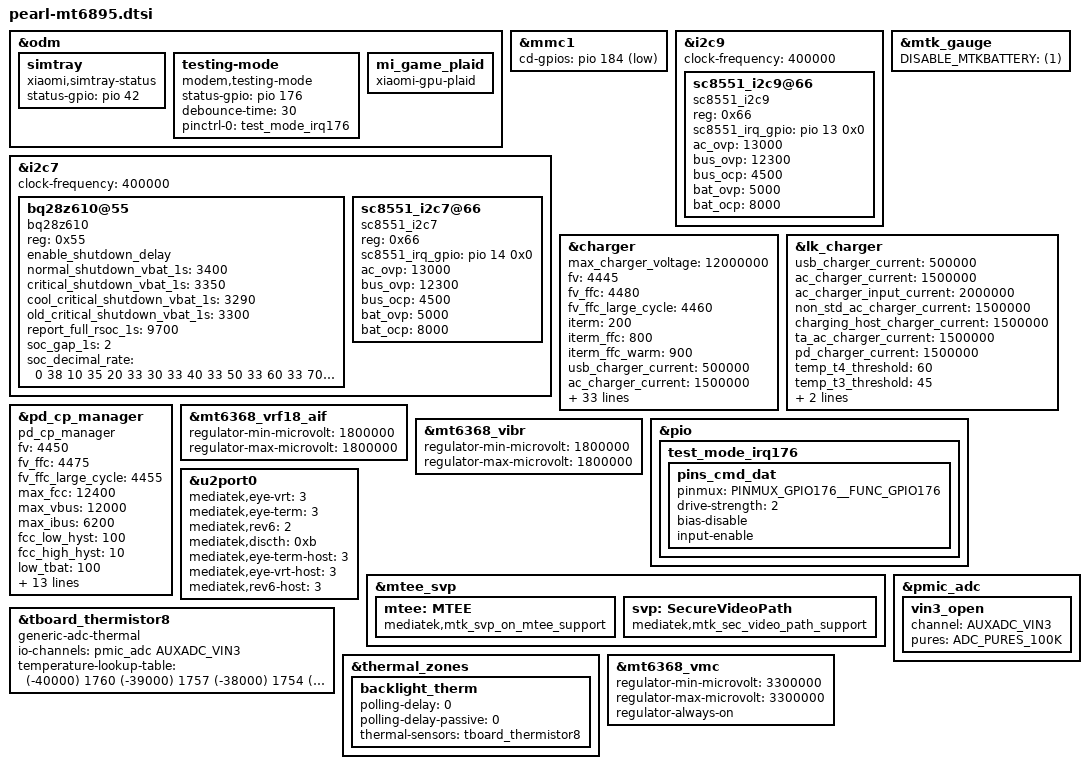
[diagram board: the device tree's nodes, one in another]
/*
this file is only for attribution of pearl
*/
#include "mediatek/xiaomi-mt6895-common.dtsi"
#include "mediatek/pearl_mt6895_camera_v4l2.dtsi"
#include "mediatek/xiaomi-pearl-mt6895-fingerprint.dtsi"
#include <dt-bindings/iio/mt635x-auxadc.h>
#include <dt-bindings/thermal/thermal.h>

&odm {
	simtray {
		compatible = "xiaomi,simtray-status";
		status-gpio =	<&pio 42 0>;
	};
};

&mmc1 {
	cd-gpios = <&pio 184 0x1>;
};

&i2c9 {
	clock-frequency = <400000>;
	status = "okay";

	sc8551_i2c9@66 {
		compatible = "sc8551_i2c9";
		reg = <0x66>;
		sc8551_irq_gpio = <&pio 13 0x0>;
		ac_ovp = <13000>;
		bus_ovp = <12300>;
		bus_ocp = <4500>;
		bat_ovp = <5000>;
		bat_ocp = <8000>;
	};
};

&i2c7 {
	clock-frequency = <400000>;
	status = "okay";
	bq28z610@55 {
		compatible = "bq28z610";
		reg = <0x55>;
		enable_shutdown_delay;
		normal_shutdown_vbat_1s = <3400>;
		critical_shutdown_vbat_1s = <3350>;
		cool_critical_shutdown_vbat_1s = <3290>;
		old_critical_shutdown_vbat_1s = <3300>;
		report_full_rsoc_1s = <9700>;
		soc_gap_1s = <2>;
		soc_decimal_rate = <
			0  38
			10 35
			20 33
			30 33
			40 33
			50 33
			60 33
			70 30
			80 25
			90 20
			95 10 >;
	};

	sc8551_i2c7@66 {
		compatible = "sc8551_i2c7";
		reg = <0x66>;
		sc8551_irq_gpio = <&pio 14 0x0>;
		ac_ovp = <13000>;
		bus_ovp = <12300>;
		bus_ocp = <4500>;
		bat_ovp = <5000>;
		bat_ocp = <8000>;
	};
};

&charger {
		max_charger_voltage = <12000000>;
		fv = <4445>;
		fv_ffc = <4480>;
		fv_ffc_large_cycle = <4460>;
		iterm = <200>;
		iterm_ffc = <800>;
		iterm_ffc_warm = <900>;
		usb_charger_current = <500000>;
		ac_charger_current = <1500000>;
		ac_charger_input_current = <1500000>;
		charging_host_charger_current = <1500000>;
		pd2_input_current = <1700000>;
		ffc_low_tbat = <150>;
		ffc_high_tbat = <480>;
		ffc_medium_tbat = <350>;
		ffc_high_soc = <95>;
		step_fallback_hyst = <25>;
		step_forward_hyst = <5>;
		jeita_fallback_hyst = <15>;
		jeita_forward_hyst = <6>;
		pearl_product;
		mt6368_moscon1_control;
		jeita_fcc_cfg = <(-100)	0	4200	1000	747
				1	50	4200	2390	2390
				51	100	4200	3386	3386
				101	150	4200	5826	5826
				151	474	4200    12400   12400
				475	600	4200	2490	2490>;
		jeita_fv_cfg = <(-100)	0	4440
				1	50	4450
				51	100	4450
				101	150	4450
				151	474	4480
				475	600	4100>;
		step_chg_cfg_low_cycle = <3000	3595	12310
					3596	4090	12310
					4091	4190	12310
					4191	4290	8875
					4291	4390	7380
					4391	4480	5786>;
		step_chg_cfg_high_cycle = <3000	3595	12310
					3596	3850	12310
					3851	4180	12310
					4181	4280	8575
					4281	4380	7180
					4381	4480	5486>;
		thermal_limit_dcp = <1800 1800 1800 1800 1800 1800 1800 1800 1800 1800 1800 1800 1700 1600 1400 1200>;
		thermal_limit_qc2 = <2500 2500 2500 2500 2500 2500 2500 2500 2500 2500 2500 2000 1500 1500 1000 500>;
		thermal_limit_qc3_18w = <2500 2500 2500 2500 2500 2500 2400 2300 2200 2100 1500 1000 800 700 600 500>;
		thermal_limit_qc3_27w = <2500 2500 2500 2500 2500 2500 2400 2300 2200 2100 1500 1000 800 700 600 500>;
		thermal_limit_qc35 = <2500 2500 2500 2500 2500 2500 2400 2300 2200 2100 1500 1000 800 700 600 500>;
		thermal_limit_pd = <12400 10000 9000 8000 7400 6100 5600 5000 4400 3500 3000 2400 2000 1500 1000 500>;
};

&mtk_gauge {
        DISABLE_MTKBATTERY = <(1)>;
};

&lk_charger {
		/* charging current */
		usb_charger_current = <500000>;
		ac_charger_current = <1500000>;
		ac_charger_input_current = <2000000>;
		non_std_ac_charger_current = <1500000>;
		charging_host_charger_current = <1500000>;
		ta_ac_charger_current = <1500000>;
		pd_charger_current = <1500000>;

		/* battery temperature protection */
		temp_t4_threshold = <60>;
		temp_t3_threshold = <45>;
		pre_charger_current = <250000>;
		fast_charge_voltage = <3100>;
};

&pd_cp_manager {
		compatible = "pd_cp_manager";
		fv = <4450>;
		fv_ffc = <4475>;
		fv_ffc_large_cycle = <4455>;
		max_fcc = <12400>;
		max_vbus = <12000>;
		max_ibus = <6200>;
		fcc_low_hyst = <100>;
		fcc_high_hyst = <10>;
		low_tbat = <100>;
		high_tbat = <480>;
		high_vbat = <4400>;
		high_soc = <95>;
		low_fcc = <2000>;
		cv_vbat = <4440>;
		cv_vbat_ffc = <4470>;
		cv_vbat_ffc_large_cycle = <4450>;
		cv_ibat = <2000>;
		cv_ibat_bypass = <1300>;
		vbus_low_gap_div = <400>;
		vbus_high_gap_div = <600>;
		min_pdo_vbus = <8000>;
		max_pdo_vbus = <11000>;

};

&mt6368_vrf18_aif {
	regulator-min-microvolt = <1800000>;
	regulator-max-microvolt = <1800000>;
};

&mt6368_vibr {
	regulator-min-microvolt = <1800000>;
	regulator-max-microvolt = <1800000>;
};

&pio {
	test_mode_irq176: test_mode_irq176 {
                pins_cmd_dat {
			pinmux = <PINMUX_GPIO176__FUNC_GPIO176>;
			drive-strength = <2>;
			bias-disable;
			input-enable;
		};
	};
};

&odm {
	testing-mode {
		compatible = "modem,testing-mode";
		status-gpio = <&pio 176 0>;
		debounce-time = <30>;
		pinctrl-names = "default";
		pinctrl-0 = <&test_mode_irq176 >;
	};
};

&odm {
	mi_game_plaid {
		compatible = "xiaomi-gpu-plaid";
	};
};

&u2port0{
		mediatek,eye-vrt = <3>;
		mediatek,eye-term = <3>;
		mediatek,rev6 = <2>;
		mediatek,discth = <0xb>;
		mediatek,eye-term-host = <3>;
		mediatek,eye-vrt-host = <3>;
		mediatek,rev6-host = <3>;
};

&mtee_svp {
	mtee: MTEE {
                   compatible = "mediatek,mtk_svp_on_mtee_support";
	};

	svp: SecureVideoPath {
                   compatible = "mediatek,mtk_sec_video_path_support";
	};
};

&pmic_adc {
	vin3_open {
		channel = <AUXADC_VIN3>;
		pures = <ADC_PURES_100K>;
	};
};

&tboard_thermistor8 {
		compatible = "generic-adc-thermal";
		#thermal-sensor-cells = <0>;
		io-channels = <&pmic_adc AUXADC_VIN3>;
		io-channel-names = "sensor-channel";
		temperature-lookup-table = <
			(-40000) 1760
			(-39000) 1757
			(-38000) 1754
			(-37000) 1751
			(-36000) 1747
			(-35000) 1744
			(-34000) 1740
			(-33000) 1736
			(-32000) 1731
			(-31000) 1727
			(-30000) 1722
			(-29000) 1716
			(-28000) 1711
			(-27000) 1705
			(-26000) 1699
			(-25000) 1693
			(-24000) 1686
			(-23000) 1679
			(-22000) 1672
			(-21000) 1664
			(-20000) 1656
			(-19000) 1648
			(-18000) 1639
			(-17000) 1630
			(-16000) 1620
			(-15000) 1610
			(-14000) 1599
			(-13000) 1588
			(-12000) 1577
			(-11000) 1565
			(-10000) 1553
			(-9000) 1540
			(-8000) 1527
			(-7000) 1514
			(-6000) 1500
			(-5000) 1485
			(-4000) 1470
			(-3000) 1455
			(-2000) 1439
			(-1000) 1423
			0 1406
			1000 1389
			2000 1372
			3000 1354
			4000 1335
			5000 1317
			6000 1298
			7000 1279
			8000 1259
			9000 1239
			10000 1219
			11000 1198
			12000 1178
			13000 1157
			14000 1136
			15000 1115
			16000 1093
			17000 1072
			18000 1050
			19000 1029
			20000 1007
			21000 986
			22000 964
			23000 943
			24000 921
			25000 900
			26000 879
			27000 858
			28000 837
			29000 816
			30000 796
			31000 775
			32000 755
			33000 736
			34000 716
			35000 697
			36000 678
			37000 659
			38000 641
			39000 623
			40000 605
			41000 588
			42000 571
			43000 555
			44000 538
			45000 523
			46000 507
			47000 492
			48000 477
			49000 463
			50000 449
			51000 435
			52000 422
			53000 409
			54000 396
			55000 384
			56000 372
			57000 360
			58000 349
			59000 338
			60000 327
			61000 317
			62000 307
			63000 297
			64000 288
			65000 279
			66000 270
			67000 261
			68000 253
			69000 245
			70000 237
			71000 230
			72000 222
			73000 215
			74000 209
			75000 202
			76000 196
			77000 189
			78000 183
			79000 178
			80000 172
			81000 167
			82000 161
			83000 156
			84000 151
			85000 147
			86000 142
			87000 138
			88000 133
			89000 129
			90000 125
			91000 121
			92000 118
			93000 114
			94000 111
			95000 107
			96000 104
			97000 101
			98000 98
			99000 95
			100000 92
			101000 89
			102000 87
			103000 84
			104000 81
			105000 79
			106000 77
			107000 74
			108000 72
			109000 70
			110000 68
			111000 66
			112000 64
			113000 62
			114000 61
			115000 59
			116000 57
			117000 56
			118000 54
			119000 52
			120000 51
			121000 50
			122000 48
			123000 47
			124000 46
			125000 44>;
};

&thermal_zones {
	backlight_therm: backlight_therm {
		polling-delay = <0>; /* milliseconds */
		polling-delay-passive = <0>; /* milliseconds */
		thermal-sensors = <&tboard_thermistor8>;
	};
};

&mt6368_vmc {
	regulator-min-microvolt = <3300000>;
	regulator-max-microvolt = <3300000>;
	regulator-always-on;
};

#include "xiaomi-pearl-mt6895-display.dtsi"
#include "mediatek/pearl-audio-overlay.dtsi"
#include "xiaomi-pearl-mt6895-touch.dtsi"
